# STM32H743 register map
Vendor: STMicroelectronics; File version: 1.0
STM32H743 USART1, generated by SiliconTruth
Registers are 32-bit, read-write, reset 0x0 unless marked. A register's access mark holds for its fields unless they carry their own. Offsets are from the block's base; lines under a group give offsets from that group; [hi:lo] are bit positions; {n}, {i} and the like mark numbered series; 'fields as' and 'values as' point back to an identical list; <NAME> marks a mode.

## Memory map
0x40011000 USART1 size 0x10 — USART1 peripheral

## USART1 — USART1 peripheral
Base 0x40011000
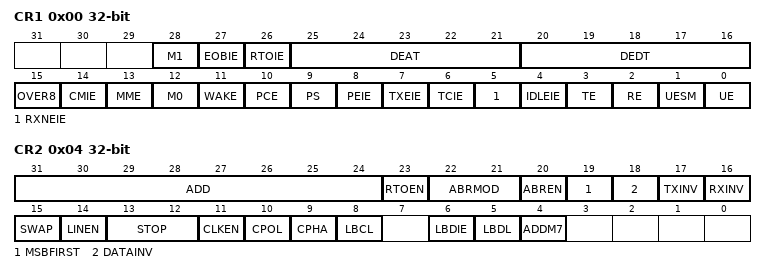
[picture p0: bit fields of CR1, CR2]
0x00 CR1
  [28] M1 — Word length bit 1
  [27] EOBIE — End of block interrupt enable
  [26] RTOIE — Receiver timeout interrupt enable
  [25:21] DEAT — Driver enable assertion time
  [20:16] DEDT — Driver enable de-assertion time
  [15] OVER8 — Oversampling mode
  [14] CMIE — Character match interrupt enable
  [13] MME — Mute mode enable
  [12] M0 — Word length bit 0
  [11] WAKE — Receiver wakeup method
  [10] PCE — Parity control enable
  [9] PS — Parity selection
  [8] PEIE — Parity error interrupt enable
  [7] TXEIE — TXE interrupt enable
  [6] TCIE — Transmission complete interrupt enable
  [5] RXNEIE — RXNE interrupt enable
  [4] IDLEIE — IDLE interrupt enable
  [3] TE — Transmitter enable
  [2] RE — Receiver enable
  [1] UESM — USART enable in Stop mode
  [0] UE — USART enable
0x04 CR2
  [31:24] ADD — Address of the USART node
  [23] RTOEN — Receiver timeout enable
  [22:21] ABRMOD — Auto baud rate mode
  [20] ABREN — Auto baud rate enable
  [19] MSBFIRST — Most significant bit first
  [18] DATAINV — Binary data inversion
  [17] TXINV — TX pin active level inversion
  [16] RXINV — RX pin active level inversion
  [15] SWAP — Swap TX/RX pins
  [14] LINEN — LIN mode enable
  [13:12] STOP — STOP bits
  [11] CLKEN — Clock enable
  [10] CPOL — Clock polarity
  [9] CPHA — Clock phase
  [8] LBCL — Last bit clock pulse
  [6] LBDIE — LIN break detection interrupt enable
  [5] LBDL — LIN break detection length
  [4] ADDM7 — 7-bit / 4-bit address detection
0x0C BRR
  [15:0] BRR — USART baud rate divider
